# PIC32MZ1064DAR169 device description
Architecture: MIPS; Family: PIC32MZDA; Series: PIC32MZ
Registers are 32-bit, read-write, no defined reset value unless marked. A register's access mark holds for its fields unless they carry their own. Offsets are from the block's base; [hi:lo] are bit positions; {n}, {i} and the like mark numbered series; 'fields as' and 'values as' point back to an identical list.

## GLCD
Instances: GLCD 0x1f8ea000 in periph_indep
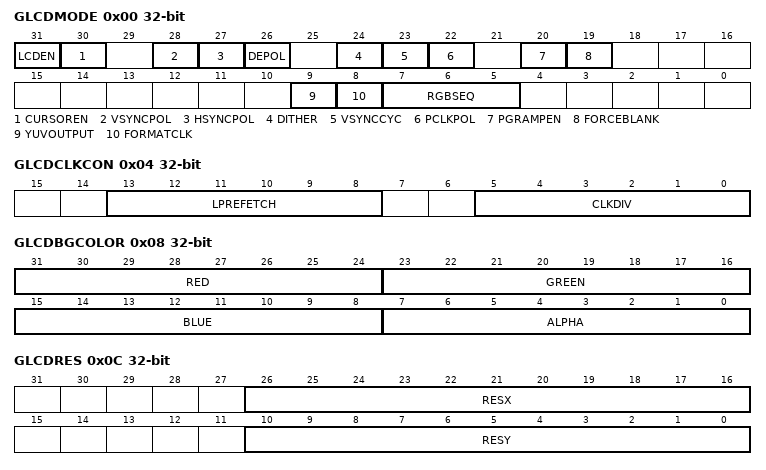
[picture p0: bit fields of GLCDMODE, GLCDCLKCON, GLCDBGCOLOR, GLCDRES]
0x00 GLCDMODE — Graphics LCD Controller Mode Register
  [31] LCDEN — LCD Controller Module Enable bit
    1=LCD Controller module is enabled; 0=LCD Controller module is not enabled
  [30] CURSOREN — Programmable Cursor Enable bit
    1=Programmable cursor is enabled; 0=Programmable cursor is enabled
  [28] VSYNCPOL — Vertical Sync Polarity bit
    1=VSYNC polarity is negative; 0=VSYNC polarity is positive
  [27] HSYNCPOL — Horizontal Sync Polarity bit
    1=HSYNC polarity is negative; 0=HSYNC polarity is positive
  [26] DEPOL — DE Polarity bit
    1=DE polarity is negative; 0=DE polarity is positive
  [24] DITHER — Dithering Enable bit
    1=Dithering is enabled; 0=Dithering is not enabled
  [23] VSYNCCYC — Vertical Sync for Single Cycle Per Line Enable bit
    1=VSYNC for a single cycle per line is enabled; 0=VSYNC for a single cycle per line is not enabled
  [22] PCLKPOL — Pixel Clock Out Polarity bit
    1=Pixel clock out polarity is negative; 0=Pixel clock out polarity is positive
  [20] PGRAMPEN — Palette Gamma Ramp Enable bit
    1=Palette gamma ramp is enabled; 0=Palette gamma ramp is not enabled
  [19] FORCEBLANK — Force Output to Blank bit
    1=Forces output to blank; 0=No effect
  [9] YUVOUTPUT — YUV Output Enable bit
    1=YUV is enabled; 0=RGB is enabled
  [8] FORMATCLK — Formatting Clock Divide Enable bit
    1=Formatting clock is not divided; 0=Formatting clock is divided
  [7:5] RGBSEQ — RGB Sequential Modes bit
    7=BT.656; 6=YUYV; 0=Parallel RGB (RGB888 RGB666 RGB332)
0x04 GLCDCLKCON — Graphics LCD Controller Clock Control Register
  [13:8] LPREFETCH
  [5:0] CLKDIV — Clock Divider bits
    31=Divided by 31; 30=Divided by 30; 29=Divided by 29; {v}=Divided by {v} (v=0..3)
0x08 GLCDBGCOLOR — Graphics LCD Controller Background Color Register
  [31:24] RED, [23:16] GREEN, [15:8] BLUE, [7:0] ALPHA
0x0C GLCDRES — Graphics LCD Controller Resolution Register
  [26:16] RESX, [10:0] RESY
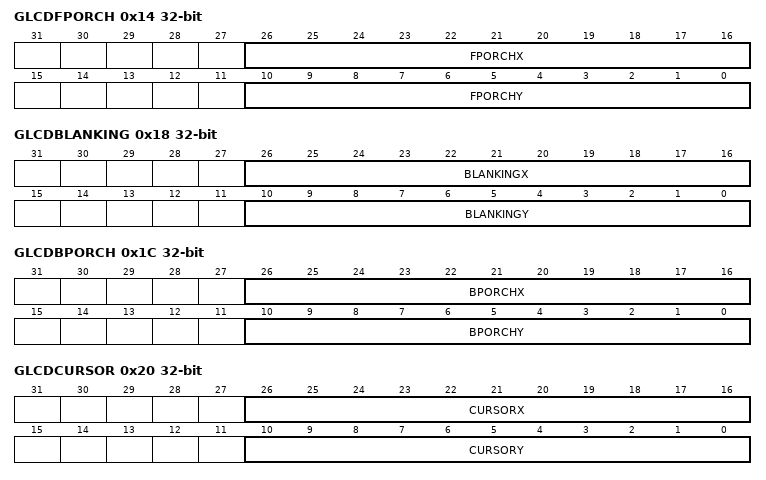
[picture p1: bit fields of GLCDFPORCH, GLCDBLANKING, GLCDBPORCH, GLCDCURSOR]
0x14 GLCDFPORCH — Graphics LCD Controller Front Porch Register
  [26:16] FPORCHX, [10:0] FPORCHY
0x18 GLCDBLANKING — Graphics LCD Controller Blanking Register
  [26:16] BLANKINGX, [10:0] BLANKINGY
0x1C GLCDBPORCH — Graphics LCD Controller Back Porch Register
  [26:16] BPORCHX, [10:0] BPORCHY
0x20 GLCDCURSOR — Graphics LCD Controller Cursor Register
  [26:16] CURSORX, [10:0] CURSORY
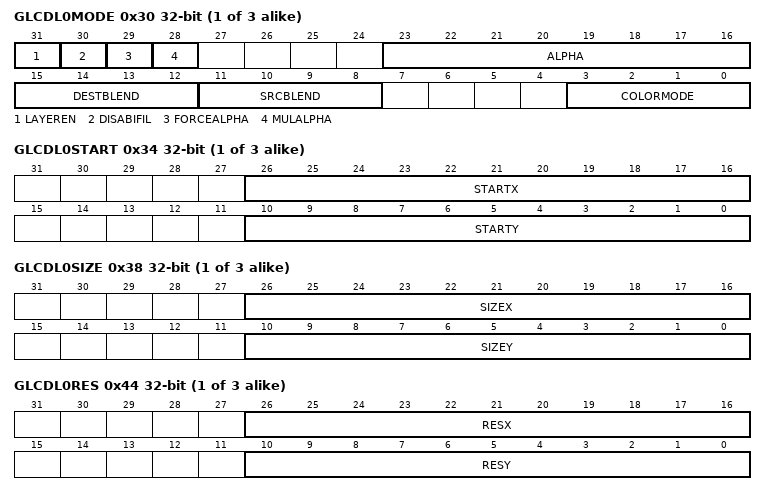
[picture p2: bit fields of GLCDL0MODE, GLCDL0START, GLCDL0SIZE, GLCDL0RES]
{0x30+0x20*i} GLCDL{i}MODE (i=0..2) — Graphics LCD Controller Layer x Mode Register (X = 0-2)
  [31] LAYEREN — Layer Enable bit
    1=Layer is enabled; 0=Layer is not enabled
  [30] DISABIFIL — Disable Bilinear Filtering bit
    1=Bilinear filtering is enabled; 0=Bilinear filtering is not enabled
  [29] FORCEALPHA — Force Alpha with Global Alpha bit
    1=Force alpha with global alpha is enabled; 0=Force alpha with global alpha is not enabled
  [28] MULALPHA — Premultiply Image Alpha bit
    1=Premultiply image alpha is enabled; 0=Premultiply image alpha is not enabled
  [23:16] ALPHA
  [15:12] DESTBLEND — Destinary Blending Function bits
    13=Blend inverted destination; 10=Blend alpha destination; 7=Blend inverted source and inverted global; 6=Blend inverted global; 5=Blend inverted source; 4=Blend alpha source and alpha global; 3=Blend alpha global; 2=Blend alpha source; 1=Blend white; 0=Blend black
  [11:8] SRCBLEND — Source Blending Function bits
    values as DESTBLEND
  [3:0] COLORMODE — Color Mode bits
    11=RGB888 color format; 10=YUYV color format; 9=L4 gray scale/palette format; 8=L1 gray scale/palette format; 7=L8 gray scale/palette format; 6=32-bit ARGB8888 color format; 5=16-bit RGB565 color format; 4=8-bit RGB332 color format; 2=32-bit RGBA8888 color format; 1=16-bit RGBA5551 color format; 0=8-bit color palette look-up table (LUT8)
{0x34+0x20*i} GLCDL{i}START (i=0..2)
  [26:16] STARTX, [10:0] STARTY
{0x38+0x20*i} GLCDL{i}SIZE (i=0..2)
  [26:16] SIZEX, [10:0] SIZEY
{0x3C+0x20*i} GLCDL{i}BADDR (i=0..2)
  [31:0] BASEADDR
{0x40+0x20*i} GLCDL{i}STRIDE (i=0..2)
  [15:0] STRIDE
{0x44+0x20*i} GLCDL{i}RES (i=0..2)
  [26:16] RESX, [10:0] RESY
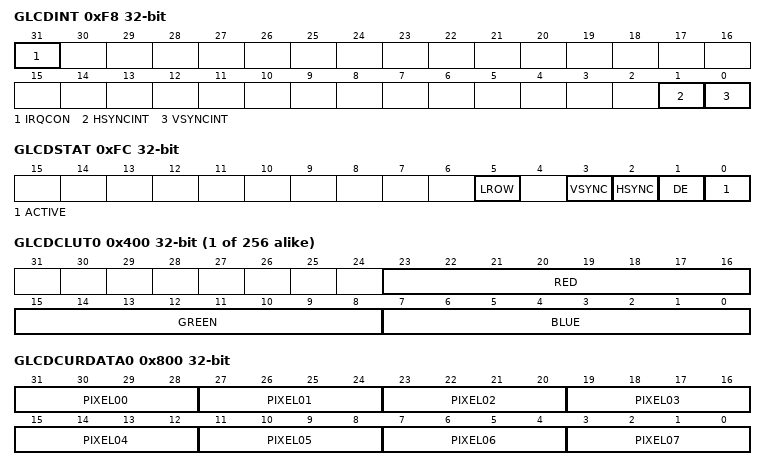
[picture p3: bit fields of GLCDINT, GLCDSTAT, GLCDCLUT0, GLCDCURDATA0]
0xF8 GLCDINT — Graphics LCD Controller Interrupt Register
  [31] IRQCON — IRQ Triggering Control bit
    1=Edge triggering is enabled; 0=Level triggering is enabled
  [1] HSYNCINT
  [0] VSYNCINT — VSYNC Interrupt Enable bit
    1=VSYNC interrupt is enabled; 0=VSYNC interrupt is not enabled
0xFC GLCDSTAT ro — Graphics LCD Controller Status Register
  [5] LROW — Last Row bit
    1=Last row is currently being displayed; 0=Last row is not currently being displayed
  [3] VSYNC
  [2] HSYNC
  [1] DE
  [0] ACTIVE — Active bit
    1=LCD Controller is not in active vertical blanking; 0=LCD Controller is in active vertical blanking
{0x400+4i} GLCDCLUT{i} (i=0..255)
  [23:16] RED, [15:8] GREEN, [7:0] BLUE
0x800 GLCDCURDATA0
  [31-4n:28-4n] PIXEL{n:02} (n=0..7)
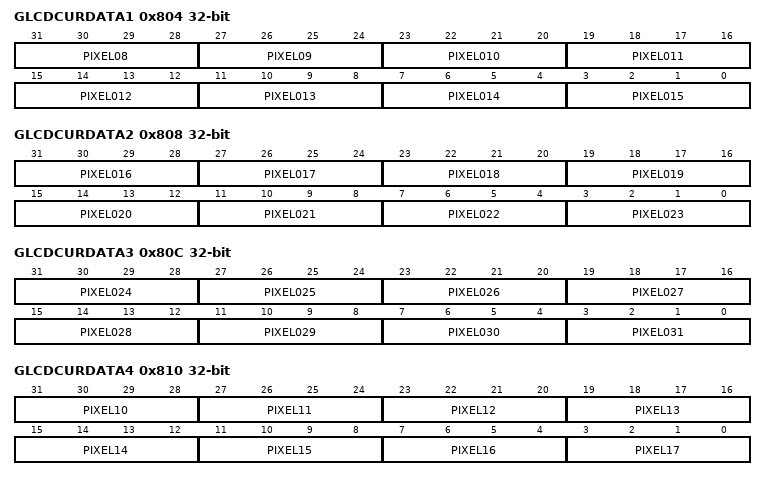
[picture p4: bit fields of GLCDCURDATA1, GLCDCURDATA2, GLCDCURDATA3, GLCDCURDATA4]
0x804 GLCDCURDATA1
  [31:28] PIXEL08, [27:24] PIXEL09, [63-4n:60-4n] PIXEL{n:03} (n=10..15)
0x808 GLCDCURDATA2
  [95-4n:92-4n] PIXEL{n:03} (n=16..23)
0x80C GLCDCURDATA3
  [127-4n:124-4n] PIXEL{n:03} (n=24..31)
0x810 GLCDCURDATA4
  [71-4n:68-4n] PIXEL{n} (n=10..17)
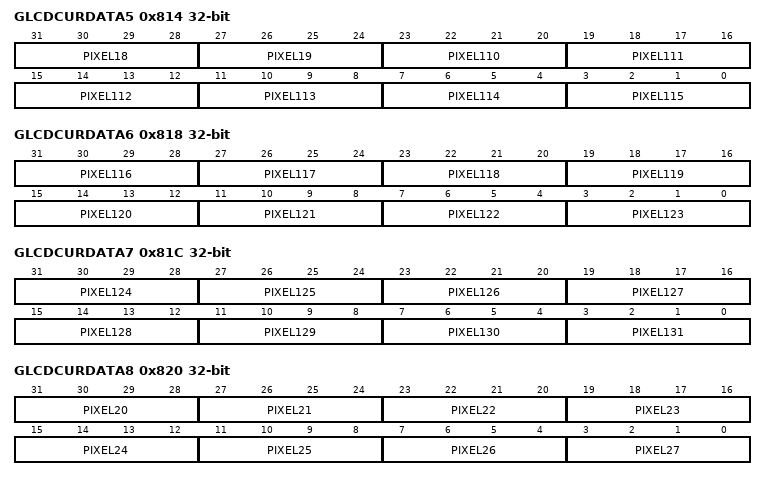
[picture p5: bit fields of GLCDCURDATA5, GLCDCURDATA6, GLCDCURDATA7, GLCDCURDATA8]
0x814 GLCDCURDATA5
  [31:28] PIXEL18, [27:24] PIXEL19, [463-4n:460-4n] PIXEL{n} (n=110..115)
0x818 GLCDCURDATA6
  [495-4n:492-4n] PIXEL{n} (n=116..123)
0x81C GLCDCURDATA7
  [527-4n:524-4n] PIXEL{n} (n=124..131)
0x820 GLCDCURDATA8
  [111-4n:108-4n] PIXEL{n} (n=20..27)
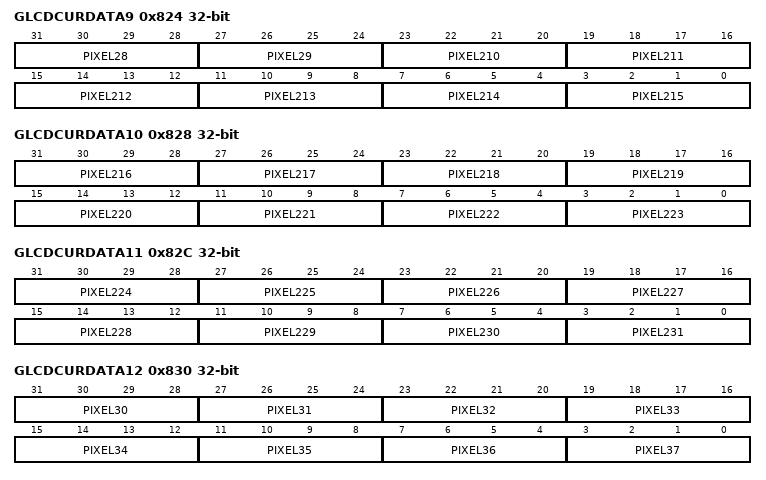
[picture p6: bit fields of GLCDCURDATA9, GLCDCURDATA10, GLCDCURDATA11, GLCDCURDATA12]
0x824 GLCDCURDATA9
  [31:28] PIXEL28, [27:24] PIXEL29, [863-4n:860-4n] PIXEL{n} (n=210..215)
0x828 GLCDCURDATA10
  [895-4n:892-4n] PIXEL{n} (n=216..223)
0x82C GLCDCURDATA11
  [927-4n:924-4n] PIXEL{n} (n=224..231)
0x830 GLCDCURDATA12
  [151-4n:148-4n] PIXEL{n} (n=30..37)
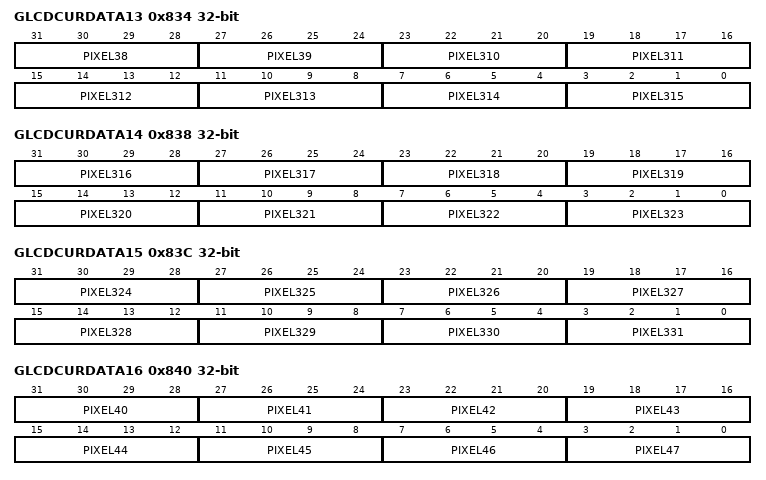
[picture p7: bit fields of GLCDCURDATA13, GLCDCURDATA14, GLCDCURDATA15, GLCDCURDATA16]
0x834 GLCDCURDATA13
  [31:28] PIXEL38, [27:24] PIXEL39, [1263-4n:1260-4n] PIXEL{n} (n=310..315)
0x838 GLCDCURDATA14
  [1295-4n:1292-4n] PIXEL{n} (n=316..323)
0x83C GLCDCURDATA15
  [1327-4n:1324-4n] PIXEL{n} (n=324..331)
0x840 GLCDCURDATA16
  [191-4n:188-4n] PIXEL{n} (n=40..47)
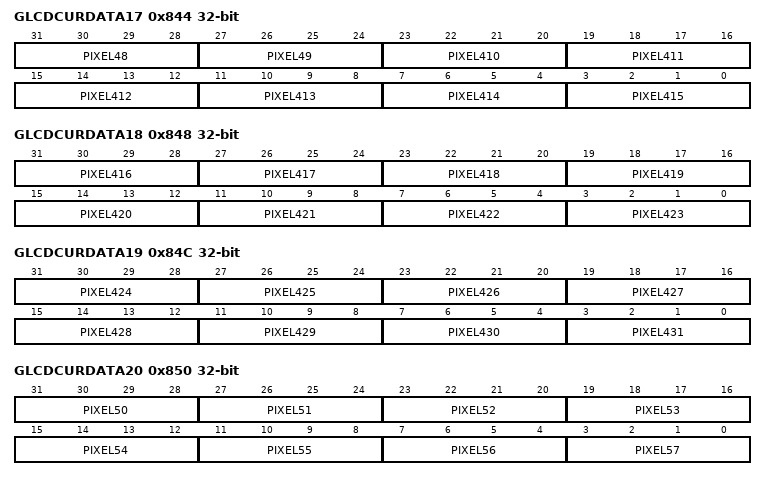
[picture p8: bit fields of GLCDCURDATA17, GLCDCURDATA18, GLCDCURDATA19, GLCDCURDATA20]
0x844 GLCDCURDATA17
  [31:28] PIXEL48, [27:24] PIXEL49, [1663-4n:1660-4n] PIXEL{n} (n=410..415)
0x848 GLCDCURDATA18
  [1695-4n:1692-4n] PIXEL{n} (n=416..423)
0x84C GLCDCURDATA19
  [1727-4n:1724-4n] PIXEL{n} (n=424..431)
0x850 GLCDCURDATA20
  [231-4n:228-4n] PIXEL{n} (n=50..57)
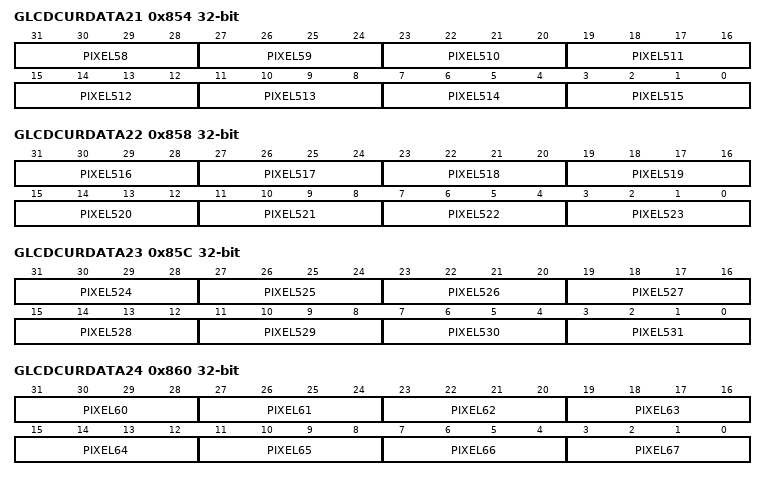
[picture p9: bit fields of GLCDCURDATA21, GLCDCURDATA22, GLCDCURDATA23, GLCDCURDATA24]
0x854 GLCDCURDATA21
  [31:28] PIXEL58, [27:24] PIXEL59, [2063-4n:2060-4n] PIXEL{n} (n=510..515)
0x858 GLCDCURDATA22
  [2095-4n:2092-4n] PIXEL{n} (n=516..523)
0x85C GLCDCURDATA23
  [2127-4n:2124-4n] PIXEL{n} (n=524..531)
0x860 GLCDCURDATA24
  [271-4n:268-4n] PIXEL{n} (n=60..67)
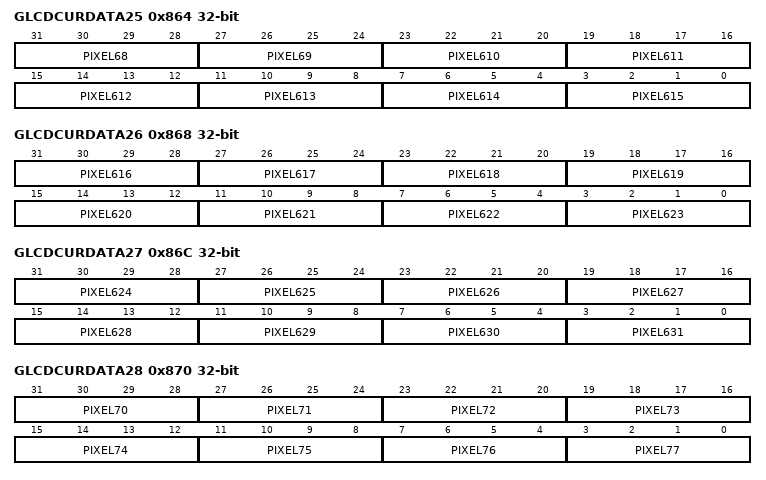
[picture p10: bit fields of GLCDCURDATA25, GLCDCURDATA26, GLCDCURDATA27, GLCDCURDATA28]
0x864 GLCDCURDATA25
  [31:28] PIXEL68, [27:24] PIXEL69, [2463-4n:2460-4n] PIXEL{n} (n=610..615)
0x868 GLCDCURDATA26
  [2495-4n:2492-4n] PIXEL{n} (n=616..623)
0x86C GLCDCURDATA27
  [2527-4n:2524-4n] PIXEL{n} (n=624..631)
0x870 GLCDCURDATA28
  [311-4n:308-4n] PIXEL{n} (n=70..77)
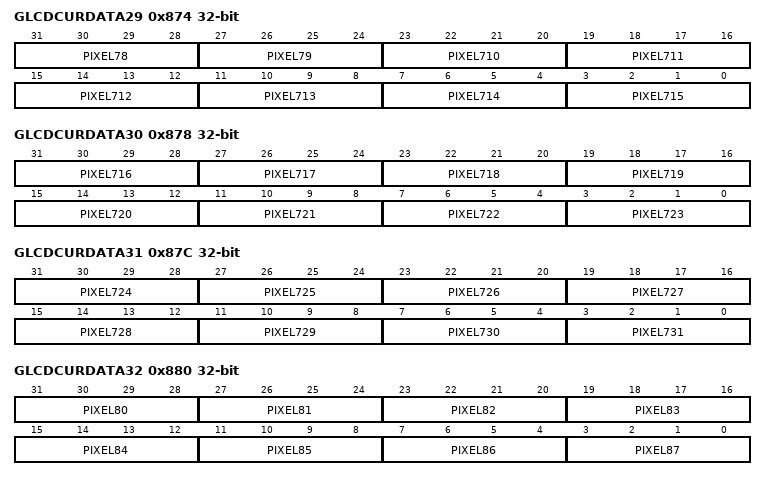
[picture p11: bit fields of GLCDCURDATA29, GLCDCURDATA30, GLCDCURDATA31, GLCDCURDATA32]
0x874 GLCDCURDATA29
  [31:28] PIXEL78, [27:24] PIXEL79, [2863-4n:2860-4n] PIXEL{n} (n=710..715)
0x878 GLCDCURDATA30
  [2895-4n:2892-4n] PIXEL{n} (n=716..723)
0x87C GLCDCURDATA31
  [2927-4n:2924-4n] PIXEL{n} (n=724..731)
0x880 GLCDCURDATA32
  [351-4n:348-4n] PIXEL{n} (n=80..87)
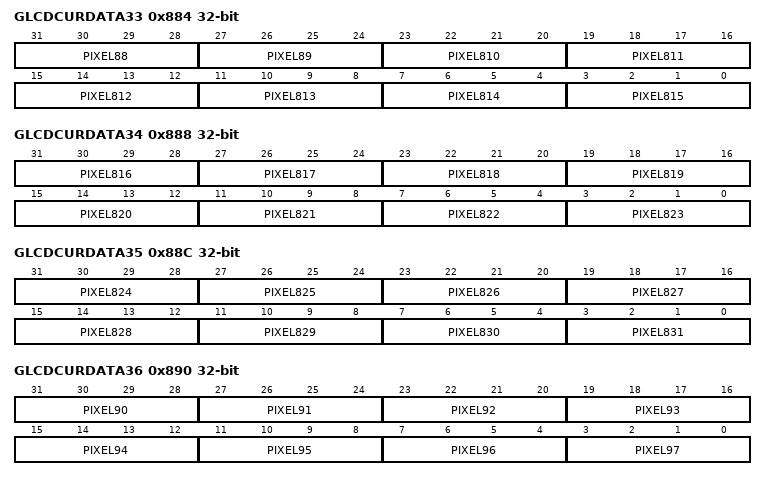
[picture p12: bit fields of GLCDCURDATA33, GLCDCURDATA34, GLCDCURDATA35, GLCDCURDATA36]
0x884 GLCDCURDATA33
  [31:28] PIXEL88, [27:24] PIXEL89, [3263-4n:3260-4n] PIXEL{n} (n=810..815)
0x888 GLCDCURDATA34
  [3295-4n:3292-4n] PIXEL{n} (n=816..823)
0x88C GLCDCURDATA35
  [3327-4n:3324-4n] PIXEL{n} (n=824..831)
0x890 GLCDCURDATA36
  [391-4n:388-4n] PIXEL{n} (n=90..97)
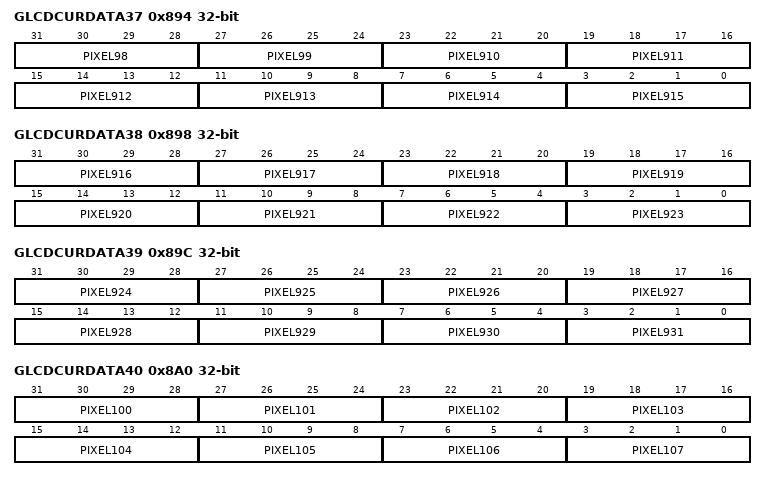
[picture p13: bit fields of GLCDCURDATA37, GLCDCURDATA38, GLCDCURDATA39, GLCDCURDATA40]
0x894 GLCDCURDATA37
  [31:28] PIXEL98, [27:24] PIXEL99, [3663-4n:3660-4n] PIXEL{n} (n=910..915)
0x898 GLCDCURDATA38
  [3695-4n:3692-4n] PIXEL{n} (n=916..923)
0x89C GLCDCURDATA39
  [3727-4n:3724-4n] PIXEL{n} (n=924..931)
0x8A0 GLCDCURDATA40
  [431-4n:428-4n] PIXEL{n} (n=100..107)
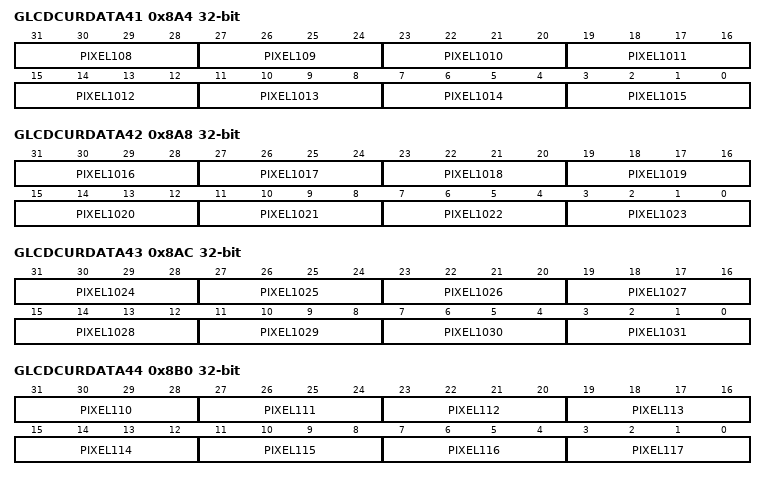
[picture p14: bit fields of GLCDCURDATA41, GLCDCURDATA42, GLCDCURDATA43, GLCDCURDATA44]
0x8A4 GLCDCURDATA41
  [31:28] PIXEL108, [27:24] PIXEL109, [4063-4n:4060-4n] PIXEL{n} (n=1010..1015)
0x8A8 GLCDCURDATA42
  [4095-4n:4092-4n] PIXEL{n} (n=1016..1023)
0x8AC GLCDCURDATA43
  [4127-4n:4124-4n] PIXEL{n} (n=1024..1031)
0x8B0 GLCDCURDATA44
  [471-4n:468-4n] PIXEL{n} (n=110..117)
0x8B4 GLCDCURDATA45
  [31:28] PIXEL118, [27:24] PIXEL119, [4463-4n:4460-4n] PIXEL{n} (n=1110..1115)
0x8B8 GLCDCURDATA46
  [4495-4n:4492-4n] PIXEL{n} (n=1116..1123)
0x8BC GLCDCURDATA47
  [4527-4n:4524-4n] PIXEL{n} (n=1124..1131)
0x8C0 GLCDCURDATA48
  [511-4n:508-4n] PIXEL{n} (n=120..127)
0x8C4 GLCDCURDATA49
  [31:28] PIXEL128, [27:24] PIXEL129, [4863-4n:4860-4n] PIXEL{n} (n=1210..1215)
0x8C8 GLCDCURDATA50
  [4895-4n:4892-4n] PIXEL{n} (n=1216..1223)
0x8CC GLCDCURDATA51
  [4927-4n:4924-4n] PIXEL{n} (n=1224..1231)
0x8D0 GLCDCURDATA52
  [551-4n:548-4n] PIXEL{n} (n=130..137)
0x8D4 GLCDCURDATA53
  [31:28] PIXEL138, [27:24] PIXEL139, [5263-4n:5260-4n] PIXEL{n} (n=1310..1315)
0x8D8 GLCDCURDATA54
  [5295-4n:5292-4n] PIXEL{n} (n=1316..1323)
0x8DC GLCDCURDATA55
  [5327-4n:5324-4n] PIXEL{n} (n=1324..1331)
0x8E0 GLCDCURDATA56
  [591-4n:588-4n] PIXEL{n} (n=140..147)
0x8E4 GLCDCURDATA57
  [31:28] PIXEL148, [27:24] PIXEL149, [5663-4n:5660-4n] PIXEL{n} (n=1410..1415)
0x8E8 GLCDCURDATA58
  [5695-4n:5692-4n] PIXEL{n} (n=1416..1423)
0x8EC GLCDCURDATA59
  [5727-4n:5724-4n] PIXEL{n} (n=1424..1431)
0x8F0 GLCDCURDATA60
  [631-4n:628-4n] PIXEL{n} (n=150..157)
0x8F4 GLCDCURDATA61
  [31:28] PIXEL158, [27:24] PIXEL159, [6063-4n:6060-4n] PIXEL{n} (n=1510..1515)
0x8F8 GLCDCURDATA62
  [6095-4n:6092-4n] PIXEL{n} (n=1516..1523)
0x8FC GLCDCURDATA63
  [6127-4n:6124-4n] PIXEL{n} (n=1524..1531)
0x900 GLCDCURDATA64
  [671-4n:668-4n] PIXEL{n} (n=160..167)
0x904 GLCDCURDATA65
  [31:28] PIXEL168, [27:24] PIXEL169, [6463-4n:6460-4n] PIXEL{n} (n=1610..1615)
0x908 GLCDCURDATA66
  [6495-4n:6492-4n] PIXEL{n} (n=1616..1623)
0x90C GLCDCURDATA67
  [6527-4n:6524-4n] PIXEL{n} (n=1624..1631)
0x910 GLCDCURDATA68
  [711-4n:708-4n] PIXEL{n} (n=170..177)
0x914 GLCDCURDATA69
  [31:28] PIXEL178, [27:24] PIXEL179, [6863-4n:6860-4n] PIXEL{n} (n=1710..1715)
0x918 GLCDCURDATA70
  [6895-4n:6892-4n] PIXEL{n} (n=1716..1723)
0x91C GLCDCURDATA71
  [6927-4n:6924-4n] PIXEL{n} (n=1724..1731)
0x920 GLCDCURDATA72
  [751-4n:748-4n] PIXEL{n} (n=180..187)
0x924 GLCDCURDATA73
  [31:28] PIXEL188, [27:24] PIXEL189, [7263-4n:7260-4n] PIXEL{n} (n=1810..1815)
0x928 GLCDCURDATA74
  [7295-4n:7292-4n] PIXEL{n} (n=1816..1823)
0x92C GLCDCURDATA75
  [7327-4n:7324-4n] PIXEL{n} (n=1824..1831)
0x930 GLCDCURDATA76
  [791-4n:788-4n] PIXEL{n} (n=190..197)
0x934 GLCDCURDATA77
  [31:28] PIXEL198, [27:24] PIXEL199, [7663-4n:7660-4n] PIXEL{n} (n=1910..1915)
0x938 GLCDCURDATA78
  [7695-4n:7692-4n] PIXEL{n} (n=1916..1923)
0x93C GLCDCURDATA79
  [7727-4n:7724-4n] PIXEL{n} (n=1924..1931)
0x940 GLCDCURDATA80
  [831-4n:828-4n] PIXEL{n} (n=200..207)
0x944 GLCDCURDATA81
  [31:28] PIXEL208, [27:24] PIXEL209, [8063-4n:8060-4n] PIXEL{n} (n=2010..2015)
0x948 GLCDCURDATA82
  [8095-4n:8092-4n] PIXEL{n} (n=2016..2023)
0x94C GLCDCURDATA83
  [8127-4n:8124-4n] PIXEL{n} (n=2024..2031)
0x950 GLCDCURDATA84
  [871-4n:868-4n] PIXEL{n} (n=210..217)
0x954 GLCDCURDATA85
  [31:28] PIXEL218, [27:24] PIXEL219, [8463-4n:8460-4n] PIXEL{n} (n=2110..2115)
0x958 GLCDCURDATA86
  [8495-4n:8492-4n] PIXEL{n} (n=2116..2123)
0x95C GLCDCURDATA87
  [8527-4n:8524-4n] PIXEL{n} (n=2124..2131)
0x960 GLCDCURDATA88
  [911-4n:908-4n] PIXEL{n} (n=220..227)
0x964 GLCDCURDATA89
  [31:28] PIXEL228, [27:24] PIXEL229, [8863-4n:8860-4n] PIXEL{n} (n=2210..2215)
0x968 GLCDCURDATA90
  [8895-4n:8892-4n] PIXEL{n} (n=2216..2223)
0x96C GLCDCURDATA91
  [8927-4n:8924-4n] PIXEL{n} (n=2224..2231)
0x970 GLCDCURDATA92
  [951-4n:948-4n] PIXEL{n} (n=230..237)
0x974 GLCDCURDATA93
  [31:28] PIXEL238, [27:24] PIXEL239, [9263-4n:9260-4n] PIXEL{n} (n=2310..2315)
0x978 GLCDCURDATA94
  [9295-4n:9292-4n] PIXEL{n} (n=2316..2323)
0x97C GLCDCURDATA95
  [9327-4n:9324-4n] PIXEL{n} (n=2324..2331)
0x980 GLCDCURDATA96
  [991-4n:988-4n] PIXEL{n} (n=240..247)
0x984 GLCDCURDATA97
  [31:28] PIXEL248, [27:24] PIXEL249, [9663-4n:9660-4n] PIXEL{n} (n=2410..2415)
0x988 GLCDCURDATA98
  [9695-4n:9692-4n] PIXEL{n} (n=2416..2423)
0x98C GLCDCURDATA99
  [9727-4n:9724-4n] PIXEL{n} (n=2424..2431)
0x990 GLCDCURDATA100
  [1031-4n:1028-4n] PIXEL{n} (n=250..257)
0x994 GLCDCURDATA101
  [31:28] PIXEL258, [27:24] PIXEL259, [10063-4n:10060-4n] PIXEL{n} (n=2510..2515)
0x998 GLCDCURDATA102
  [10095-4n:10092-4n] PIXEL{n} (n=2516..2523)
0x99C GLCDCURDATA103
  [10127-4n:10124-4n] PIXEL{n} (n=2524..2531)
0x9A0 GLCDCURDATA104
  [1071-4n:1068-4n] PIXEL{n} (n=260..267)
0x9A4 GLCDCURDATA105
  [31:28] PIXEL268, [27:24] PIXEL269, [10463-4n:10460-4n] PIXEL{n} (n=2610..2615)
0x9A8 GLCDCURDATA106
  [10495-4n:10492-4n] PIXEL{n} (n=2616..2623)
0x9AC GLCDCURDATA107
  [10527-4n:10524-4n] PIXEL{n} (n=2624..2631)
0x9B0 GLCDCURDATA108
  [1111-4n:1108-4n] PIXEL{n} (n=270..277)
0x9B4 GLCDCURDATA109
  [31:28] PIXEL278, [27:24] PIXEL279, [10863-4n:10860-4n] PIXEL{n} (n=2710..2715)
0x9B8 GLCDCURDATA110
  [10895-4n:10892-4n] PIXEL{n} (n=2716..2723)
0x9BC GLCDCURDATA111
  [10927-4n:10924-4n] PIXEL{n} (n=2724..2731)
0x9C0 GLCDCURDATA112
  [1151-4n:1148-4n] PIXEL{n} (n=280..287)
0x9C4 GLCDCURDATA113
  [31:28] PIXEL288, [27:24] PIXEL289, [11263-4n:11260-4n] PIXEL{n} (n=2810..2815)
0x9C8 GLCDCURDATA114
  [11295-4n:11292-4n] PIXEL{n} (n=2816..2823)
0x9CC GLCDCURDATA115
  [11327-4n:11324-4n] PIXEL{n} (n=2824..2831)
0x9D0 GLCDCURDATA116
  [1191-4n:1188-4n] PIXEL{n} (n=290..297)
0x9D4 GLCDCURDATA117
  [31:28] PIXEL298, [27:24] PIXEL299, [11663-4n:11660-4n] PIXEL{n} (n=2910..2915)
0x9D8 GLCDCURDATA118
  [11695-4n:11692-4n] PIXEL{n} (n=2916..2923)
0x9DC GLCDCURDATA119
  [11727-4n:11724-4n] PIXEL{n} (n=2924..2931)
0x9E0 GLCDCURDATA120
  [1231-4n:1228-4n] PIXEL{n} (n=300..307)
0x9E4 GLCDCURDATA121
  [31:28] PIXEL308, [27:24] PIXEL309, [12063-4n:12060-4n] PIXEL{n} (n=3010..3015)
0x9E8 GLCDCURDATA122
  [12095-4n:12092-4n] PIXEL{n} (n=3016..3023)
0x9EC GLCDCURDATA123
  [12127-4n:12124-4n] PIXEL{n} (n=3024..3031)
0x9F0 GLCDCURDATA124
  [1271-4n:1268-4n] PIXEL{n} (n=310..317)
0x9F4 GLCDCURDATA125
  [31:28] PIXEL318, [27:24] PIXEL319, [12463-4n:12460-4n] PIXEL{n} (n=3110..3115)
0x9F8 GLCDCURDATA126
  [12495-4n:12492-4n] PIXEL{n} (n=3116..3123)
0x9FC GLCDCURDATA127
  [12527-4n:12524-4n] PIXEL{n} (n=3124..3131)
{0xA00+4i} GLCDCURLUT{i} (i=0..15) — Graphics LCD Controller Cursor LUT Register x (x = 0-15)
  [23:16] RED, [15:8] GREEN, [7:0] BLUE

## Notices in the file
Copyright (c) 2017 Microchip Technology Inc.
SPDX-License-Identifier: Apache-2.0
Licensed under the Apache License, Version 2.0 (the "License");
you may not use this file except in compliance with the License.
You may obtain a copy of the License at
http://www.apache.org/licenses/LICENSE-2.0
Unless required by applicable law or agreed to in writing, software
distributed under the License is distributed on an "AS IS" BASIS,
WITHOUT WARRANTIES OR CONDITIONS OF ANY KIND, either express or implied.
See the License for the specific language governing permissions and
limitations under the License.
